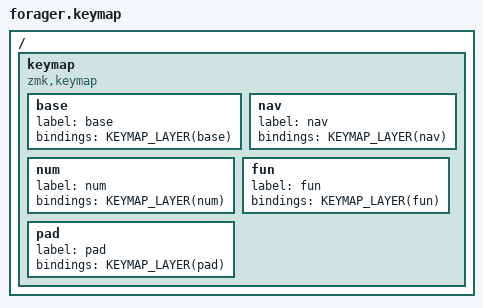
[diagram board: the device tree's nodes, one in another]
/*
 * forager (carrefinho) — thin keymap. Split 3x5+2 on xiao_ble; hardware from the
 * carrefinho/forager-zmk-module module. Its matrix is a plain contiguous 0..33 core,
 * so it uses the shared generic adapter. All content lives in config/shared/.
 * (Built bare; the forager's RGB LED status widget is a later opt-in.)
 */

#include <behaviors.dtsi>
#include <dt-bindings/zmk/keys.h>
#include <dt-bindings/zmk/bt.h>
#include <dt-bindings/zmk/outputs.h>

#include "geometry/geom_3x5_2.h"

#include "shared/keys_de.h"
#include "shared/settings.dtsi"
#include "shared/behaviors.dtsi"
#include "shared/macros.dtsi"
#include "shared/combos.dtsi"
#include "shared/core_blocks.dtsi"

/ {
    keymap {
        compatible = "zmk,keymap";

        base { label = "base"; bindings = <KEYMAP_LAYER(base)>; };
        nav  { label = "nav";  bindings = <KEYMAP_LAYER(nav)>;  };
        num  { label = "num";  bindings = <KEYMAP_LAYER(num)>;  };
        fun  { label = "fun";  bindings = <KEYMAP_LAYER(fun)>;  };
        pad  { label = "pad";  bindings = <KEYMAP_LAYER(pad)>;  };
    };
};
